# S6E1A1 register map
File version: 1.2
CPU: 
Registers are 32-bit, read-write, reset 0x0 unless marked. A register's access mark holds for its fields unless they carry their own. Offsets are from the block's base; [hi:lo] are bit positions; 'fields as' and 'values as' point back to an identical list.

## SWWDT — Software Watchdog Timer
Base 0x40012000
0x00 WDOGLOAD reset 0xFFFFFFFF — Software Watchdog Timer Load Register
0x04 WDOGVALUE ro reset 0xFFFFFFFF — Software Watchdog Timer Value Register
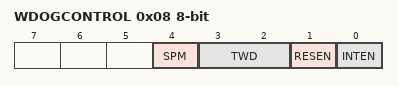
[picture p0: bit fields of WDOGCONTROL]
0x08 WDOGCONTROL 8-bit — Software Watchdog Timer Control Register
  [4] SPM — Software Watchdog window watchdog mode enable bit
  [3:2] TWD — Timing window setting bit of the software watchdog
  [1] RESEN — Reset enable bit of the software watchdog
  [0] INTEN — Interrupt and counter enable bit of the software watchdog
0x0C WDOGINTCLR — Software Watchdog Timer Clear Register
0x10 WDOGRIS 8-bit ro — Software Watchdog Timer Interrupt Status Register
  [0] RIS — Software watchdog interrupt status bit
0x18 WDOGSPMC 8-bit — Software Watchdog Timer Window Watchdog Mode Control Register
  [0] TGR — Software watchdog trigger type bit
0xC00 WDOGLOCK — Software Watchdog Timer Lock Register

## DTIM — Dual Timer
Base 0x40015000
0x00 TIMER1LOAD (DualTimer1 view) — Load Register
0x04 TIMER1VALUE ro reset 0xFFFFFFFF — Value Register
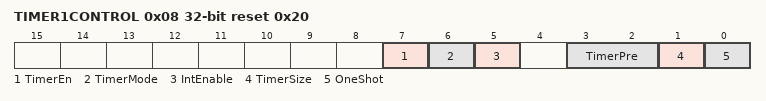
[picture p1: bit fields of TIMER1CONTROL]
0x08 TIMER1CONTROL reset 0x20 — Control Register
  [7] TimerEn — Enable bit
  [6] TimerMode — Mode bit
  [5] IntEnable — Interrupt enable bit
  [3:2] TimerPre — Prescale bits
  [1] TimerSize — Counter size bit
  [0] OneShot — One-shot mode bit
0x0C TIMER1INTCLR wo — Interrupt Clear Register
0x10 TIMER1RIS ro — Interrupt Status Register
  [0] TIMER1RIS — Interrupt Status Register bit
0x14 TIMER1MIS ro — Masked Interrupt Status Register
  [0] TIMER1MIS — Masked Interrupt Status bit
0x18 TIMER1BGLOAD — Background Load Register
0x20 TIMER2LOAD reset not defined — Load Register
0x24 TIMER2VALUE reset not defined — Value Register
0x28 TIMER2CONTROL reset not defined — Control Register
0x2C TIMER2INTCLR reset not defined — Interrupt Clear Register
0x30 TIMER2RIS reset not defined — Interrupt Status Register
0x34 TIMER2MIS reset not defined — Masked Interrupt Status Register
0x38 TIMER2BGLOAD reset not defined — Background Load Register

## BT0 — Base Timer 0
Base 0x40025000
Same registers: BT1 0x40025040, BT2 0x40025080, BT3 0x400250C0
0x00 PWM_PCSR 16-bit (PWM view) — PWM Cycle Set Register
0x00 PPG_PRLL 16-bit (PPG view) — LOW Width Reload Register
0x00 RT_PCSR 16-bit (RT view) — Cycle Set Register
0x04 PWM_PDUT 16-bit (PWM view) — PWM Duty Set Register
0x04 PPG_PRLH 16-bit (PPG view) — HIGH Width Reload Register
0x04 PWC_DTBF 16-bit ro (PWC view) — Data Buffer Register
0x08 PWM_TMR 16-bit ro (PWM view) — Timer Register
0x08 PPG_TMR 16-bit ro (PPG view) — Timer Register
0x08 RT_TMR 16-bit ro (RT view) — Timer Register
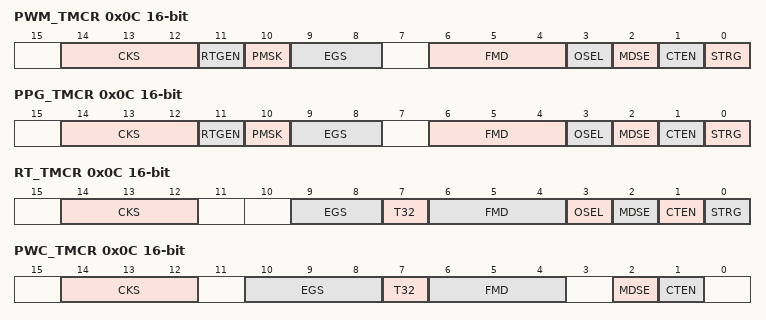
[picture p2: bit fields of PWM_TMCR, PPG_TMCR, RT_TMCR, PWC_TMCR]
0x0C PWM_TMCR 16-bit (PWM view) — Timer Control Register
  [14:12] CKS — Count clock selection bits
  [11] RTGEN — Restart enable bit
  [10] PMSK — Pulse output mask bit
  [9:8] EGS — Trigger input edge selection bits
  [6:4] FMD — Timer function selection bits
  [3] OSEL — Output polarity specification bit
  [2] MDSE — Mode selection bit
  [1] CTEN — Count operation enable bit
  [0] STRG — Software trigger bit
0x0C PPG_TMCR 16-bit (PPG view) — Timer Control Register
  fields as PWM_TMCR
0x0C RT_TMCR 16-bit (RT view) — Timer Control Register
  [14:12] CKS — Count clock selection bits
  [9:8] EGS — Slection bits of trigger input edge and gate function level
  [7] T32 — 32-bit timer selection bit
  [6:4] FMD — Timer function selection bits
  [3] OSEL — Output polarity specification bit
  [2] MDSE — Mode selection bit
  [1] CTEN — Timer enable bit
  [0] STRG — Software trigger bit
0x0C PWC_TMCR 16-bit (PWC view) — Timer Control Register
  [14:12] CKS — Count clock selection bits
  [10:8] EGS — Measurement edge selection bits
  [7] T32 — 32-bit timer selection bit
  [6:4] FMD — Timer function selection bits
  [2] MDSE — Mode selection bit
  [1] CTEN — Timer enable bit
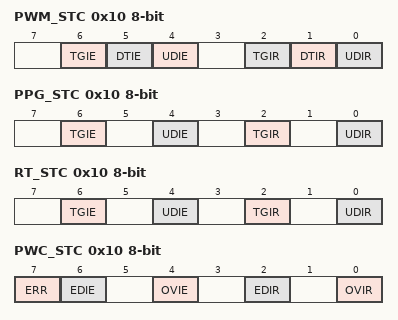
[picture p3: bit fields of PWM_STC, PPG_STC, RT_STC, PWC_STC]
0x10 PWM_STC 8-bit (PWM view) — Status Control Register
  [6] TGIE — Trigger interrupt request enable bit
  [5] DTIE — Duty match interrupt request enable bit
  [4] UDIE — Underflow interrupt request enable bit
  [2] TGIR — Trigger interrupt request bit
  [1] DTIR — Duty match interrupt request bit
  [0] UDIR — Underflow interrupt request bit
0x10 PPG_STC 8-bit (PPG view) — Status Control Register
  [6] TGIE — Trigger interrupt request enable bit
  [4] UDIE — Underflow interrupt request enable bit
  [2] TGIR — Trigger interrupt request bit
  [0] UDIR — Underflow interrupt request bit
0x10 RT_STC 8-bit (RT view) — Status Control Register
  fields as PPG_STC
0x10 PWC_STC 8-bit (PWC view) — Status Control Register
  [7] ERR ro — Error flag bit
  [6] EDIE — Measurement completion interrupt request enable bit
  [4] OVIE — Overflow interrupt request enable bit
  [2] EDIR ro — Measurement completion interrupt request bit
  [0] OVIR — Overflow interrupt request bit
0x11 PWM_TMCR2 8-bit (PWM view) — Timer Control Register 2
  [0] CKS3 — Count clock selection bit
0x11 PPG_TMCR2 8-bit (PPG view) — Timer Control Register 2
  [0] CKS3 — Count clock selection bit
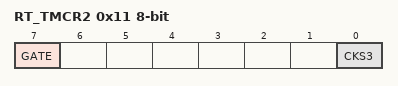
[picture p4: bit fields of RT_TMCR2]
0x11 RT_TMCR2 8-bit (RT view) — Timer Control Register 2
  [7] GATE — Gate Input Enable bit
  [0] CKS3 — Count clock selection bit
0x11 PWC_TMCR2 8-bit (PWC view) — Timer Control Register 2
  [0] CKS3 — Count clock selection bit
